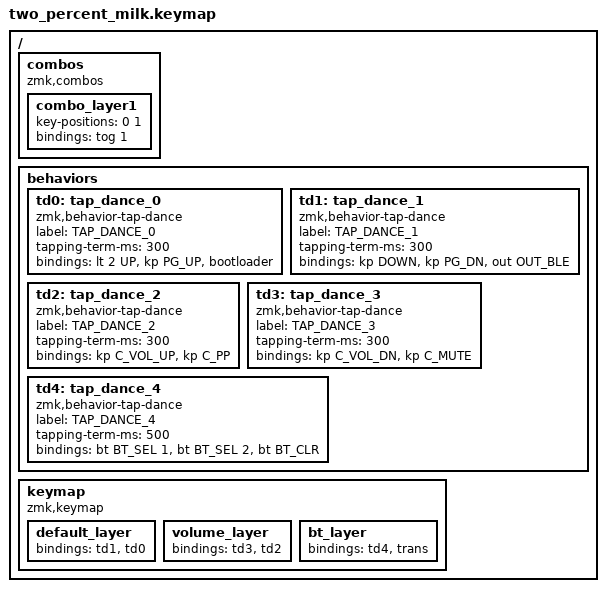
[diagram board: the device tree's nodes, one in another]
/*
 * Copyright (c) 2022 The ZMK Contributors
 *
 * SPDX-License-Identifier: MIT
 */

#include <behaviors.dtsi>
#include <dt-bindings/zmk/keys.h>
#include <dt-bindings/zmk/bt.h>
#include <dt-bindings/zmk/outputs.h>
//#include <dt-bindings/zmk/mouse.h>

/ {
    combos {
        compatible = "zmk,combos";
        combo_layer1 {
//            timeout-ms = <50>;
            key-positions = <0 1>;
            bindings = <&tog 1>;
        };
    };
};

/ {
    behaviors {
        td0: tap_dance_0 {
            compatible = "zmk,behavior-tap-dance";
            label = "TAP_DANCE_0";
            #binding-cells = <0>;
            tapping-term-ms = <300>;
            bindings = <&lt 2 UP>, <&kp PG_UP>, <&bootloader>;
        };
        td1: tap_dance_1 {
            compatible = "zmk,behavior-tap-dance";
            label = "TAP_DANCE_1";
            #binding-cells = <0>;
            tapping-term-ms = <300>;
            bindings = <&kp DOWN>, <&kp PG_DN>, <&out OUT_BLE>;

        };
        td2: tap_dance_2 {
            compatible = "zmk,behavior-tap-dance";
            label = "TAP_DANCE_2";
            #binding-cells = <0>;
            tapping-term-ms = <300>;
            bindings = <&kp C_VOL_UP>, <&kp C_PP>;
        };
        td3: tap_dance_3 {
            compatible = "zmk,behavior-tap-dance";
            label = "TAP_DANCE_3";
            #binding-cells = <0>;
            tapping-term-ms = <300>;
            bindings = <&kp C_VOL_DN>, <&kp C_MUTE>;
        };
        td4: tap_dance_4 {
            compatible = "zmk,behavior-tap-dance";
            label = "TAP_DANCE_4";
            #binding-cells = <0>;
            tapping-term-ms = <500>;
            bindings = <&bt BT_SEL 1>, <&bt BT_SEL 2>, <&bt BT_CLR>;
        };
    };

    keymap {
        compatible = "zmk,keymap";
 
        default_layer {
            bindings = <
                &td1
                &td0
            >;
        };
        volume_layer {
            bindings = <
                &td3
                &td2
            >;
        };
        bt_layer {
            bindings = <
                &td4
                &trans
            >;
        };
    };
};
